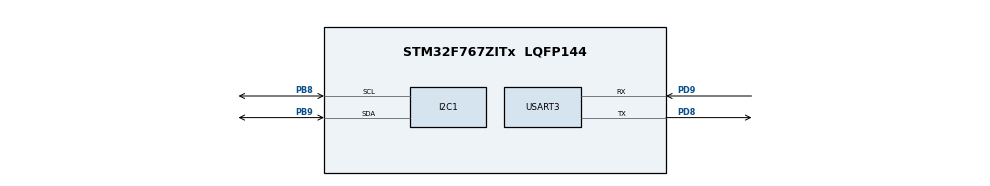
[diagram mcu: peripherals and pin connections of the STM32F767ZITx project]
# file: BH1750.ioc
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Mcu.Family=STM32F7
Mcu.Name=STM32F767ZITx
Mcu.Package=LQFP144
NVIC.PriorityGroup=NVIC_PRIORITYGROUP_4
NVIC.TIM7_IRQn=true\:0\:0\:false\:false\:true\:true\:true\:true
PB8.Mode=I2C
PB8.Signal=I2C1_SCL
PB9.Mode=I2C
PB9.Signal=I2C1_SDA
PD8.Mode=Asynchronous
PD8.Signal=USART3_TX
PD9.Mode=Asynchronous
PD9.Signal=USART3_RX
ProjectManager.HeapSize=0x200
ProjectManager.StackSize=0x400
ProjectManager.TargetToolchain=Makefile
RCC.HSE_VALUE=25000000
RCC.HSI_VALUE=16000000
RCC.LSE_VALUE=32768
RCC.USBFreq_Value=96000000
RCC.VCOOutputFreq_Value=192000000
TIM7.Prescaler=8399
USART3.VirtualMode-Asynchronous=VM_ASYNC
VP_TIM7_VS_ClockSourceINT.Mode=Enable_Timer
board=custom

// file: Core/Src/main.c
/* USER CODE BEGIN Header */
/**
  ******************************************************************************
  * @file           : main.c
  * @brief          : Main program body
  ******************************************************************************
  * @attention
  *
  * Copyright (c) 2026 STMicroelectronics.
  * All rights reserved.
  *
  * This software is licensed under terms that can be found in the LICENSE file
  * in the root directory of this software component.
  * If no LICENSE file comes with this software, it is provided AS-IS.
  *
  ******************************************************************************
  */
/* USER CODE END Header */
#include "main.h"
#include "i2c.h"
#include "tim.h"
#include "usart.h"
#include "gpio.h"

/* USER CODE BEGIN Includes */
#include <stdio.h>
#include "STM32_BH1750.h"
/* USER CODE END Includes */

void SystemClock_Config(void);

int main(void)
{

  /* MCU Configuration--------------------------------------------------------*/

  /* Reset of all peripherals, Initializes the Flash interface and the Systick. */
  HAL_Init();

  /* Configure the system clock */
  SystemClock_Config();

  /* Initialize all configured peripherals */
  MX_GPIO_Init();
  MX_USART3_UART_Init();
  MX_I2C1_Init();
  MX_TIM7_Init();
  /* USER CODE BEGIN 2 */
  HAL_TIM_Base_Start_IT(&htim7);
  BH1750_Data sensor = BH1750_Init(CONT_HI_RES, ADDR_0V, &hi2c1);
  /* USER CODE END 2 */

  /* Infinite loop */
  /* USER CODE BEGIN WHILE */
  float result;
  while (1)
  {
    result = BH1750_Read(&sensor);
    printf("Уровень освещения: %d.%02d lux\r\n", (int)result,
           (int)((result - (int)result) * 100));

    /* USER CODE END WHILE */
  }
}

void SystemClock_Config(void)
{
  RCC_OscInitTypeDef RCC_OscInitStruct = {0};
  RCC_ClkInitTypeDef RCC_ClkInitStruct = {0};

  /** Configure the main internal regulator output voltage
  */
  __HAL_RCC_PWR_CLK_ENABLE();
  __HAL_PWR_VOLTAGESCALING_CONFIG(PWR_REGULATOR_VOLTAGE_SCALE3);

  /** Initializes the RCC Oscillators according to the specified parameters
  * in the RCC_OscInitTypeDef structure.
  */
  RCC_OscInitStruct.OscillatorType = RCC_OSCILLATORTYPE_HSI;
  RCC_OscInitStruct.HSIState = RCC_HSI_ON;
  RCC_OscInitStruct.HSICalibrationValue = RCC_HSICALIBRATION_DEFAULT;
  RCC_OscInitStruct.PLL.PLLState = RCC_PLL_NONE;
  if (HAL_RCC_OscConfig(&RCC_OscInitStruct) != HAL_OK)
  {
    Error_Handler();
  }

  /** Initializes the CPU, AHB and APB buses clocks
  */
  RCC_ClkInitStruct.ClockType = RCC_CLOCKTYPE_HCLK|RCC_CLOCKTYPE_SYSCLK
                              |RCC_CLOCKTYPE_PCLK1|RCC_CLOCKTYPE_PCLK2;
  RCC_ClkInitStruct.SYSCLKSource = RCC_SYSCLKSOURCE_HSI;
  RCC_ClkInitStruct.AHBCLKDivider = RCC_SYSCLK_DIV1;
  RCC_ClkInitStruct.APB1CLKDivider = RCC_HCLK_DIV1;
  RCC_ClkInitStruct.APB2CLKDivider = RCC_HCLK_DIV1;

  if (HAL_RCC_ClockConfig(&RCC_ClkInitStruct, FLASH_LATENCY_0) != HAL_OK)
  {
    Error_Handler();
  }
}

void Error_Handler(void)
{
  __disable_irq();
  while (1)
  {
  }
}
